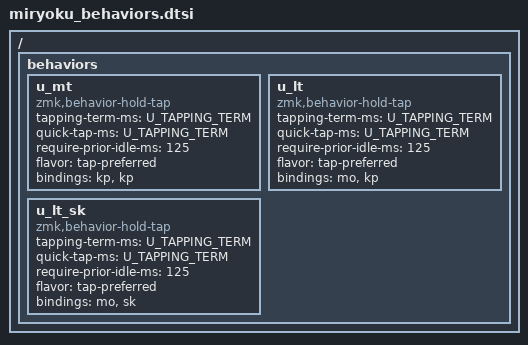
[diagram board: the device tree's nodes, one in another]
// Copyright 2022 Manna Harbour
// https://github.com/manna-harbour/miryoku

/ {
  behaviors {
    u_mt: u_mt {
      compatible = "zmk,behavior-hold-tap";
      #binding-cells = <2>;
      tapping-term-ms = <U_TAPPING_TERM>;
      quick-tap-ms = <U_TAPPING_TERM>;
      require-prior-idle-ms = <125>;
      flavor = "tap-preferred";
      bindings = <&kp>, <&kp>;
    };
    u_lt: u_lt {
      compatible = "zmk,behavior-hold-tap";
      #binding-cells = <2>;
      tapping-term-ms = <U_TAPPING_TERM>;
      quick-tap-ms = <U_TAPPING_TERM>;
      require-prior-idle-ms = <125>;
      flavor = "tap-preferred";
      bindings = <&mo>, <&kp>;
    };
    u_lt_sk: u_lt_sk {
      compatible = "zmk,behavior-hold-tap";
      // compatible = "zmk,behavior-hold-tap,behavior-sticky-key";
      #binding-cells = <2>;
      tapping-term-ms = <U_TAPPING_TERM>;
      quick-tap-ms = <U_TAPPING_TERM>;
      require-prior-idle-ms = <125>;
      flavor = "tap-preferred";
      bindings = <&mo>, <&sk>;
    };
  };
};
